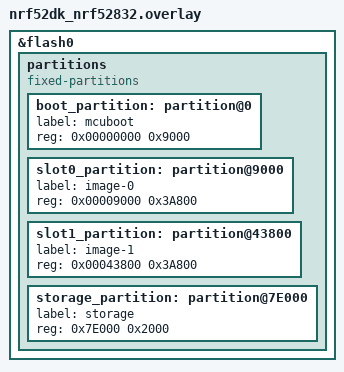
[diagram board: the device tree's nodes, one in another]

/delete-node/ &boot_partition;
/delete-node/ &slot0_partition;
/delete-node/ &slot1_partition;
/delete-node/ &storage_partition;
///delete-node/ &settings_partition;

&flash0 {

	partitions {
		compatible = "fixed-partitions";
		#address-cells = <1>;
		#size-cells = <1>;

		boot_partition: partition@0 {
			label = "mcuboot";
			reg = <0x00000000 0x9000>;
		};
		slot0_partition: partition@9000 {
			label = "image-0";
			reg = <0x00009000 0x3A800>;
		};
		slot1_partition: partition@43800 {
			label = "image-1";
			reg = <0x00043800 0x3A800>;
		};
		storage_partition: partition@7E000 {
			label = "storage";
			reg = <0x7E000 0x2000>;
		};
	};
};



// /delete-node/ &storage_partition;
// &flash0 {

// partitions {
// compatible = "fixed-partitions";
// #address-cells = <1>;
// #size-cells = <1>;

// boot_partition: partition@0 {
// label = "mcuboot";
// reg = <0x00000000 0xC000>;
// };
// slot0_partition: partition@c000 {
// label = "image-0";
// reg = <0x0000C000 0x32000>;
// };
// slot1_partition: partition@3e000 {
// label = "image-1";
// reg = <0x0003E000 0x32000>;
// };
// scratch_partition: partition@70000 {
// label = "image-scratch";
// reg = <0x00070000 0xA000>;
// };
// settings_partition: partition@7a000 {
// label = "settings";
// reg = <0x0007A000 0x00002000>;
// };
// storage_partition: partition@7c000 {
// label = "storage";
// reg = <0x0007c000 0x00004000>;
// };
// };
// };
